# AE1C1F4051920PH0_CM55_HE_View register map
Vendor: Alif Semiconductor; Series: E1; File version: 1.0
CPU: CM55 r1p0, selectable endian, MPU, FPU, double-precision FPU, DSP, VTOR, 8 interrupt priority bits, 1 SAU regions
Registers are 32-bit, read-write, reset 0x0 unless marked. A register's access mark holds for its fields unless they carry their own. Offsets are from the block's base; [hi:lo] are bit positions; lines under a group give offsets from that group; {n}, {i} and the like mark numbered series; 'fields as' and 'values as' point back to an identical list.

## LPTIMER
Base 0x42001000
{0x0+0x14*i} LPTIMER_CHANNEL_CFG[{i}] (i=0..1) group
  0x00 LPTIMER_LOADCOUNT — Timer (n) Load Count Register
    [31:0] TIMERN_LOADCOUNT — Value to be loaded into Timer (n). This is the value from which counting commences. Any value written to this register is loaded into the associated timer.
  0x04 LPTIMER_CURRENTVAL ro reset 0x80000000 — Timer (n) Current Value Register
    [31:0] TIMERN_CURRENTVALUE — Current Value of Timer (n)
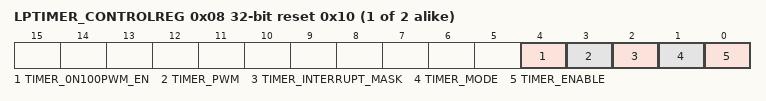
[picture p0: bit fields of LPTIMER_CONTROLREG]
  0x08 LPTIMER_CONTROLREG reset 0x10 — Timer (n) Control Register
    [4] TIMER_0N100PWM_EN ro — 0% and 100% PWM duty cycle mode for Timer (n). Hardcoded to enabled state to reduce software overhead.
      1=Enabled
    [3] TIMER_PWM — Pulse Width Modulation of Timer (n) toggle output.
      0=PWM is disabled (normal toggle); 1=PWM is enabled (PWM toggle)
    [2] TIMER_INTERRUPT_MASK — Timer interrupt mask for Timer (n).
      0=Timer (n) interrupt is unmasked; 1=Timer (n) interrupt is masked
    [1] TIMER_MODE — Timer mode for Timer (n). Note: All bits of the LPTIMERn_LOADCOUNT register must be set to 1 before enabling Timer (n) in free-running mode.
      0=Free-running count; 1=User-defined count
    [0] TIMER_ENABLE — Timer enable bit for Timer (n).
      0=Timer (n) is disabled; 1=Timer (n) is enabled
  0x0C LPTIMER_EOI ro — Timer (n) End-of-Interrupt Register
    [0] TIMERN_EOI — End-of-Interrupt for Timer (n).
  0x10 LPTIMER_INTSTAT ro — Timer (n) Interrupt Status Register
    [0] TIMERN_INTSTATUS — Interrupt status for Timer (n) after mask:
      0=Timer (n) interrupt is inactive. IRQ line is not asserted.; 1=Timer (n) interrupt is active. IRQ line is asserted.
0xA0 LPTIMERS_INTSTATUS ro — Timers Interrupt Status Register
  [1:0] TIMERS_INTSTATUS — Interrupt status of all timers after mask, where: Bit 1: LPTIMER1 Bit 0: LPTIMER0 For each bit:
    values as LPTIMER_CHANNEL_CFG[0].LPTIMER_INTSTAT.TIMERN_INTSTATUS
0xA4 LPTIMERS_EOI ro — Timers End-of-Interrupt Register
  [1:0] TIMERS_EOI — End-of-Interrupt of all timers, where: Bit 1: LPTIMER1 Bit 0: LPTIMER0
0xA8 LPTIMERS_RAWINTSTATUS ro — Timers Raw Interrupt Status Register
  [1:0] TIMERS_RAWINTSTAT — Raw interrupt status of all timers, where: Bit 1: LPTIMER1 Bit 0: LPTIMER0 For each bit:
    0=Raw Timer (n) interrupt is inactive; 1=Raw Timer (n) interrupt is active
0xAC LPTIMERS_COMP_VERSION ro reset 0x3231322A — LPTIMER Component Version
  [31:0] TIMERS_COMP_VERSION — LPTIMER version number
{0xB0+4i} LPTIMER_LOADCOUNT2[{i}] (i=0..1) — Timer (n) Load Count2 Register
  [31:0] TIMERN_LOADCOUNT2 — Value to be loaded into Timer (n) when toggle output changes from 0 to 1. This value determines the width of the high period of the toggle output.

## LPGPIO_CTRL
Base 0x42007000
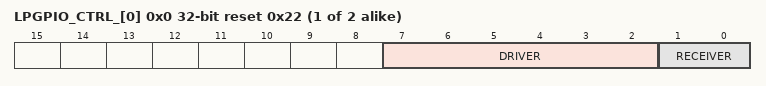
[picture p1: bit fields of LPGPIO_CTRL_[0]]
{0x0+4i} LPGPIO_CTRL_[{i}] (i=0..1) reset 0x22 — LPGPIO I/O Buffer Control Register
  [7:2] DRIVER — Driver configuration - Bit[7] selects driver mode: 0x0: Push-pull 0x1: Open drain - Bits[6-5] select driver strength: 0x0: 2 mA 0x1: 4 mA (default) 0x2: 8 mA 0x3: 12 mA - Bits[4-3] select driver disabled state: 0x0: Hi-Z 0x1: Pull-up 0x2: Pull-down 0x3: Bus keeper - Bit[2] selects slew rate: Note: Applicable only to 1.8-V I/Os (non-Flex) 0x0: Slow 0x1: Fast
  [1:0] RECEIVER — Receiver configuration - Bit[1] Schmitt trigger (hysteresis) enable: 0x0: Disabled 0x1: Enabled - Bit[0] receiver enable: 0x0: Disabled 0x1: Enabled

## LPI2C
Base 0x43009000
0x00 LPI2C_DATA — Read/Write Data Register
  [7:0] DATA — If the corresponding FIFO is not empty/full, a byte of data can be read/written to this address. From FIFO's perspective, it would be like a pop/push operation.
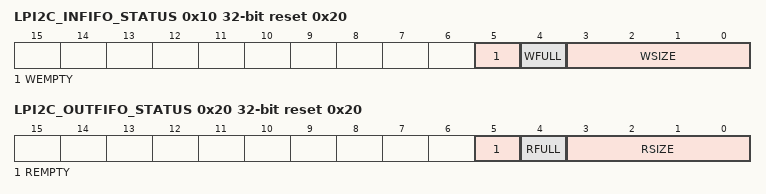
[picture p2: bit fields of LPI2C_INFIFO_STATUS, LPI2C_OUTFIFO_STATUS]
0x10 LPI2C_INFIFO_STATUS ro reset 0x20 — Inbound FIFO Status Register
  [5] WEMPTY — This field shows if the inbound FIFO is empty.
    0=Not empty; 1=Empty
  [4] WFULL — This field shows if the inbound FIFO is full.
    0=Not full; 1=Full
  [3:0] WSIZE — This field shows the number of available bytes of data in the inbound FIFO.
0x20 LPI2C_OUTFIFO_STATUS ro reset 0x20 — Outbound FIFO Status Register
  [5] REMPTY — This field shows if the outbound FIFO is empty.
    0=Not empty; 1=Empty
  [4] RFULL — This field shows if the outbound FIFO is full.
    0=Not full; 1=Full
  [3:0] RSIZE — This field shows the number of bytes of data in the outbound FIFO to be transmitted.
